# STM32L562xx register map
File version: 1.0
Registers are 32-bit, read-write, reset 0x0 unless marked. A register's access mark holds for its fields unless they carry their own. Offsets are from the block's base; [hi:lo] are bit positions; {n}, {i} and the like mark numbered series.

## FLASH — FLASH Registers
Base 0x40022000
Same registers: FLASH_S 0x50022000
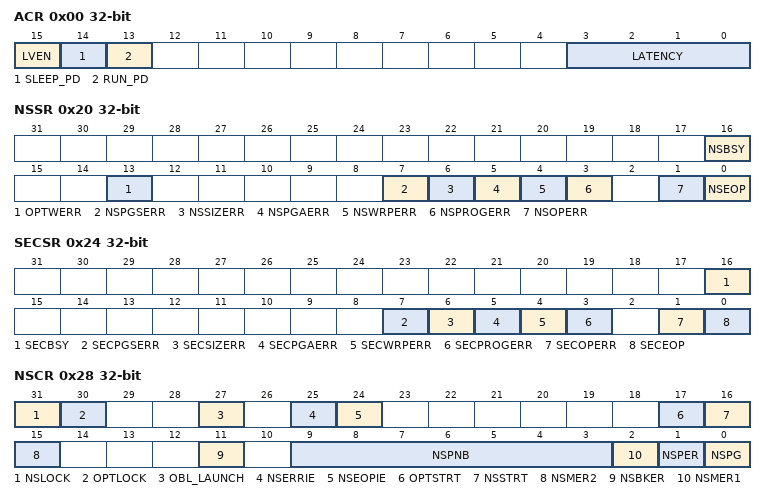
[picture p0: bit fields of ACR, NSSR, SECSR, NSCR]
0x00 ACR — FLASH access control register
  [15] LVEN — LVE A/B Flash pin low
  [14] SLEEP_PD — Flash power down mode during sleep
  [13] RUN_PD — Flash power down mode during run
  [3:0] LATENCY
    0=FLASH zero wait state; 1=FLASH one wait state; 2=FLASH two wait states; 3=FLASH three wait states; 4=FLASH four wait states; 5=FLASH five wait states; 6=FLASH six wait state; 7=FLASH Seven wait states; 8=FLASH Eight wait states; 9=FLASH nine wait states; 10=FLASH ten wait states; 11=FLASH eleven wait states; 12=FLASH twelve wait states; 13=FLASH thirteen wait states; 14=FLASH fourteen wait states; 15=FLASH fifteen wait states
0x04 PDKEYR — FLASH power down key register
0x08 NSKEYR — FLASH non-secure key register
0x0C SECKEYR — FLASH secure key register
0x10 OPTKEYR — FLASH option key register
0x14 LVEKEYR — FLASH LVE key register
0x20 NSSR — FLASH non-secure status register
  [16] NSBSY, [13] OPTWERR, [7] NSPGSERR, [6] NSSIZERR, [5] NSPGAERR, [4] NSWRPERR, [3] NSPROGERR, [1] NSOPERR, [0] NSEOP
0x24 SECSR — FLASH secure status register
  [16] SECBSY, [7] SECPGSERR, [6] SECSIZERR, [5] SECPGAERR, [4] SECWRPERR, [3] SECPROGERR, [1] SECOPERR, [0] SECEOP
0x28 NSCR — FLASH non-secure control register
  [31] NSLOCK, [30] OPTLOCK, [27] OBL_LAUNCH, [25] NSERRIE, [24] NSEOPIE, [17] OPTSTRT, [16] NSSTRT, [15] NSMER2, [11] NSBKER, [9:3] NSPNB, [2] NSMER1, [1] NSPER, [0] NSPG
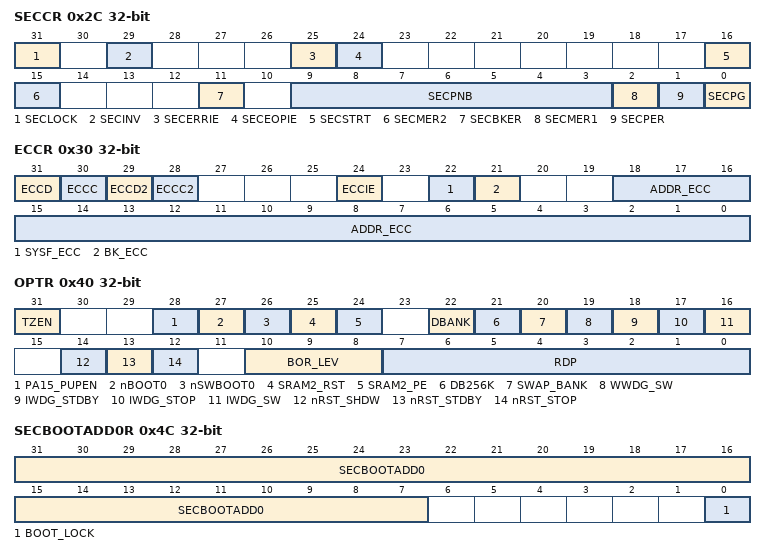
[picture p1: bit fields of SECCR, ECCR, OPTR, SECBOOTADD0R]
0x2C SECCR — FLASH secure control register
  [31] SECLOCK, [29] SECINV, [25] SECERRIE, [24] SECEOPIE, [16] SECSTRT, [15] SECMER2, [11] SECBKER, [9:3] SECPNB, [2] SECMER1, [1] SECPER, [0] SECPG
0x30 ECCR — FLASH ECC register
  [31] ECCD, [30] ECCC, [29] ECCD2, [28] ECCC2, [24] ECCIE, [22] SYSF_ECC, [21] BK_ECC, [18:0] ADDR_ECC
0x40 OPTR — FLASH option control register
  [31] TZEN, [28] PA15_PUPEN, [27] nBOOT0, [26] nSWBOOT0, [25] SRAM2_RST, [24] SRAM2_PE, [22] DBANK, [21] DB256K, [20] SWAP_BANK, [19] WWDG_SW, [18] IWDG_STDBY, [17] IWDG_STOP, [16] IWDG_SW, [14] nRST_SHDW, [13] nRST_STDBY, [12] nRST_STOP, [10:8] BOR_LEV, [7:0] RDP
0x44 NSBOOTADD0R — FLASH non-secure boot address 0 register
  [31:7] NSBOOTADD0
0x48 NSBOOTADD1R — FLASH non-secure boot address 1 register
  [31:7] NSBOOTADD1
0x4C SECBOOTADD0R — FLASH secure boot address 0 register
  [31:7] SECBOOTADD0, [0] BOOT_LOCK
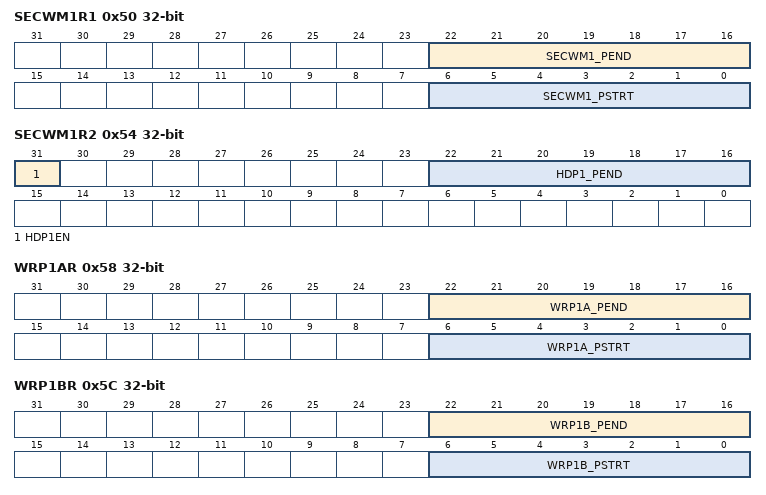
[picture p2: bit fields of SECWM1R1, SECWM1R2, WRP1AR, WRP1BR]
0x50 SECWM1R1 — FLASH watermark-based secure register 1 bank 1
  [22:16] SECWM1_PEND, [6:0] SECWM1_PSTRT
0x54 SECWM1R2 — FLASH watermark-based secure register 2 bank 1
  [31] HDP1EN, [22:16] HDP1_PEND
0x58 WRP1AR — FLASH WRP area A register bank 1
  [22:16] WRP1A_PEND, [6:0] WRP1A_PSTRT
0x5C WRP1BR — FLASH WRP area B register bank 1
  [22:16] WRP1B_PEND, [6:0] WRP1B_PSTRT
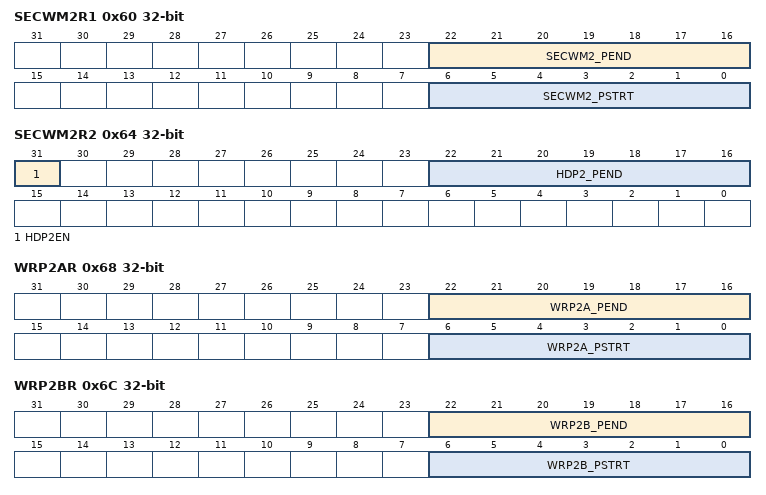
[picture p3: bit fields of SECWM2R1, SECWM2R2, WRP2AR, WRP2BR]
0x60 SECWM2R1 — FLASH watermark-based secure register 1 bank 2
  [22:16] SECWM2_PEND, [6:0] SECWM2_PSTRT
0x64 SECWM2R2 — FLASH watermark-based secure register 2 bank 2
  [31] HDP2EN, [22:16] HDP2_PEND
0x68 WRP2AR — FLASH WRP area A register bank 2
  [22:16] WRP2A_PEND, [6:0] WRP2A_PSTRT
0x6C WRP2BR — FLASH WRP area B register bank 2
  [22:16] WRP2B_PEND, [6:0] WRP2B_PSTRT
{0x7C+4i} SECBB1R{i} (i=1..4) — FLASH block-based secure bank 1
{0x9C+4i} SECBB2R{i} (i=1..4) — FLASH block-based secure bank 2
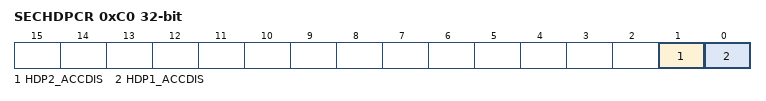
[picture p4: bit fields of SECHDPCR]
0xC0 SECHDPCR — FLASH secure HDP control register
  [1] HDP2_ACCDIS, [0] HDP1_ACCDIS
0xC4 PRIVCFGR — FLASH privilege configuration register
  [0] PRIV

## CRC — CRC calculation unit
Base 0x40023000
Same registers: CRC_S 0x50023000
0x00 DR — CRC Data register
  [31:0] DR — Data register bits
0x04 IDR — CRC Independent data register
  [31:0] IDR — General-purpose 32-bits data register bits
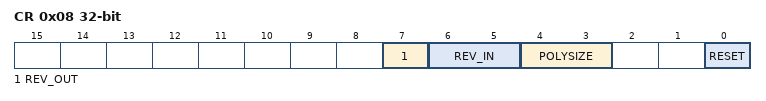
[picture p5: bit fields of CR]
0x08 CR — CRC Control register
  [7] REV_OUT — REV_OUT Reverse Output Data bits
    0=NONE (Output Data bit order not affected); 1=BIT (Output Data bit reversal done by bit)
  [6:5] REV_IN — REV_IN Reverse Input Data bits
    0=NONE (Input Data bit order not affected); 1=BYTE (Input Data bit reversal done by byte); 2=HALFWORD (Input Data bit reversal done by half-word); 3=WORD (Input Data bit reversal done by word)
  [4:3] POLYSIZE — Polynomial size bits
    0=POLYLENGTH_32B (32 bits Polynomial size); 1=POLYLENGTH_16B (16 bits Polynomial size); 2=POLYLENGTH_8B (8 bits Polynomial size); 3=POLYLENGTH_7B (7 bits Polynomial size)
  [0] RESET — RESET the CRC computation unit bit
0x10 INIT — Initial CRC value register
  [31:0] INIT — Initial CRC value bits
0x14 POL — CRC polynomial register
  [31:0] POL — Coefficients of the polynomial
